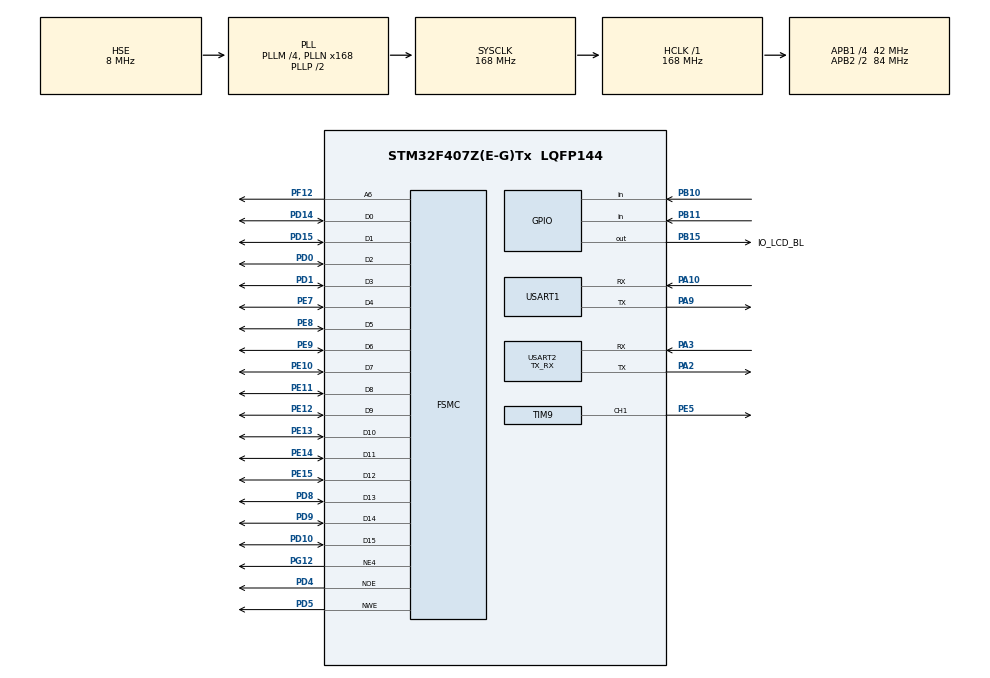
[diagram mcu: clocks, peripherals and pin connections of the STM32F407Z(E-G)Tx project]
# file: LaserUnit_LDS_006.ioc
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FSMC.AddressSetupTime1=15
FSMC.BusTurnAroundDuration1=0
FSMC.DataSetupTime1=70
FSMC.ExtendedBusTurnAroundDuration1=0
FSMC.ExtendedDataSetupTime1=15
FSMC.ExtendedMode1=FSMC_EXTENDED_MODE_ENABLE
Mcu.Family=STM32F4
Mcu.Name=STM32F407Z(E-G)Tx
Mcu.Package=LQFP144
NVIC.PriorityGroup=NVIC_PRIORITYGROUP_4
NVIC.USART2_IRQn=true\:0\:0\:false\:false\:true\:true\:true
PA10.Mode=Asynchronous
PA10.Signal=USART1_RX
PA13.Mode=Serial_Wire
PA13.Signal=SYS_JTMS-SWDIO
PA14.Mode=Serial_Wire
PA14.Signal=SYS_JTCK-SWCLK
PA2.Mode=Asynchronous
PA2.Signal=USART2_TX
PA3.Mode=Asynchronous
PA3.Signal=USART2_RX
PA9.Mode=Asynchronous
PA9.Signal=USART1_TX
PB10.GPIO_PuPd=GPIO_PULLUP
PB10.Signal=GPIO_Input
PB11.GPIO_PuPd=GPIO_PULLUP
PB11.Signal=GPIO_Input
PB15.GPIO_Label=IO_LCD_BL
PB15.PinState=GPIO_PIN_SET
PB15.Signal=GPIO_Output
PC14-OSC32_IN.Mode=LSE-External-Oscillator
PC14-OSC32_IN.Signal=RCC_OSC32_IN
PC15-OSC32_OUT.Mode=LSE-External-Oscillator
PC15-OSC32_OUT.Signal=RCC_OSC32_OUT
PD0.Signal=FSMC_D2_DA2
PD1.Signal=FSMC_D3_DA3
PD10.Signal=FSMC_D15_DA15
PD14.Signal=FSMC_D0_DA0
PD15.Signal=FSMC_D1_DA1
PD4.Signal=FSMC_NOE
PD5.Signal=FSMC_NWE
PD8.Signal=FSMC_D13_DA13
PD9.Signal=FSMC_D14_DA14
PE10.Signal=FSMC_D7_DA7
PE11.Signal=FSMC_D8_DA8
PE12.Signal=FSMC_D9_DA9
PE13.Signal=FSMC_D10_DA10
PE14.Signal=FSMC_D11_DA11
PE15.Signal=FSMC_D12_DA12
PE5.Signal=S_TIM9_CH1
PE7.Signal=FSMC_D4_DA4
PE8.Signal=FSMC_D5_DA5
PE9.Signal=FSMC_D6_DA6
PF12.Signal=FSMC_A6
PG12.Mode=NorPsramChipSelect4_1
PG12.Signal=FSMC_NE4
PH0-OSC_IN.Mode=HSE-External-Oscillator
PH0-OSC_IN.Signal=RCC_OSC_IN
PH1-OSC_OUT.Mode=HSE-External-Oscillator
PH1-OSC_OUT.Signal=RCC_OSC_OUT
ProjectManager.HeapSize=0x200
ProjectManager.StackSize=0x400
ProjectManager.TargetToolchain=STM32CubeIDE
RCC.48MHZClocksFreq_Value=84000000
RCC.AHBFreq_Value=168000000
RCC.APB1CLKDivider=RCC_HCLK_DIV4
RCC.APB1Freq_Value=42000000
RCC.APB1TimFreq_Value=84000000
RCC.APB2CLKDivider=RCC_HCLK_DIV2
RCC.APB2Freq_Value=84000000
RCC.APB2TimFreq_Value=168000000
RCC.CortexFreq_Value=168000000
RCC.HCLKFreq_Value=168000000
RCC.HSE_VALUE=8000000
RCC.HSI_VALUE=16000000
RCC.PLLM=4
RCC.PLLN=168
RCC.PLLSourceVirtual=RCC_PLLSOURCE_HSE
RCC.SYSCLKFreq_VALUE=168000000
RCC.SYSCLKSource=RCC_SYSCLKSOURCE_PLLCLK
RCC.VCOOutputFreq_Value=336000000
SH.FSMC_A6.0=FSMC_A6,A6_1
SH.FSMC_D0_DA0.0=FSMC_D0,16b-d1
SH.FSMC_D10_DA10.0=FSMC_D10,16b-d1
SH.FSMC_D11_DA11.0=FSMC_D11,16b-d1
SH.FSMC_D12_DA12.0=FSMC_D12,16b-d1
SH.FSMC_D13_DA13.0=FSMC_D13,16b-d1
SH.FSMC_D14_DA14.0=FSMC_D14,16b-d1
SH.FSMC_D15_DA15.0=FSMC_D15,16b-d1
SH.FSMC_D1_DA1.0=FSMC_D1,16b-d1
SH.FSMC_D2_DA2.0=FSMC_D2,16b-d1
SH.FSMC_D3_DA3.0=FSMC_D3,16b-d1
SH.FSMC_D4_DA4.0=FSMC_D4,16b-d1
SH.FSMC_D5_DA5.0=FSMC_D5,16b-d1
SH.FSMC_D6_DA6.0=FSMC_D6,16b-d1
SH.FSMC_D7_DA7.0=FSMC_D7,16b-d1
SH.FSMC_D8_DA8.0=FSMC_D8,16b-d1
SH.FSMC_D9_DA9.0=FSMC_D9,16b-d1
SH.FSMC_NOE.0=FSMC_NOE,Lcd1
SH.FSMC_NWE.0=FSMC_NWE,Lcd1
SH.S_TIM9_CH1.0=TIM9_CH1,PWM Generation1 CH1
TIM9.AutoReloadPreload=TIM_AUTORELOAD_PRELOAD_ENABLE
TIM9.Channel-PWM\ Generation1\ CH1=TIM_CHANNEL_1
TIM9.Period=16799
USART1.VirtualMode=VM_ASYNC
USART2.Mode=MODE_TX_RX
USART2.VirtualMode=VM_ASYNC
VP_TIM9_VS_ClockSourceINT.Mode=Internal
board=custom

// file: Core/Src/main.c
/* USER CODE BEGIN Header */
/**
  ******************************************************************************
  * @file           : main.c
  * @brief          : Main program body
  ******************************************************************************
  * @attention
  *
  * <h2><center>&copy; Copyright (c) 2021 STMicroelectronics.
  * All rights reserved.</center></h2>
  *
  * This software component is licensed by ST under BSD 3-Clause license,
  * the "License"; You may not use this file except in compliance with the
  * License. You may obtain a copy of the License at:
  *                        opensource.org/licenses/BSD-3-Clause
  *
  ******************************************************************************
  */
/* USER CODE END Header */
#include "main.h"

/* USER CODE BEGIN Includes */
#include "user_main.h"
/* USER CODE END Includes */

TIM_HandleTypeDef htim9;

UART_HandleTypeDef huart1;
UART_HandleTypeDef huart2;

SRAM_HandleTypeDef hsram1;

void SystemClock_Config(void);
static void MX_GPIO_Init(void);
static void MX_FSMC_Init(void);
static void MX_USART1_UART_Init(void);
static void MX_USART2_UART_Init(void);
static void MX_TIM9_Init(void);

int main(void)
{

  /* MCU Configuration--------------------------------------------------------*/

  /* Reset of all peripherals, Initializes the Flash interface and the Systick. */
  HAL_Init();

  /* Configure the system clock */
  SystemClock_Config();

  /* Initialize all configured peripherals */
  MX_GPIO_Init();
  MX_FSMC_Init();
  MX_USART1_UART_Init();
  MX_USART2_UART_Init();
  MX_TIM9_Init();

  /* Infinite loop */
  /* USER CODE BEGIN WHILE */
  while (1)
  {
    userMain();
    /* USER CODE END WHILE */

  }
}

void SystemClock_Config(void)
{
  RCC_OscInitTypeDef RCC_OscInitStruct = {0};
  RCC_ClkInitTypeDef RCC_ClkInitStruct = {0};

  /** Configure the main internal regulator output voltage
  */
  __HAL_RCC_PWR_CLK_ENABLE();
  __HAL_PWR_VOLTAGESCALING_CONFIG(PWR_REGULATOR_VOLTAGE_SCALE1);
  /** Initializes the RCC Oscillators according to the specified parameters
  * in the RCC_OscInitTypeDef structure.
  */
  RCC_OscInitStruct.OscillatorType = RCC_OSCILLATORTYPE_HSE;
  RCC_OscInitStruct.HSEState = RCC_HSE_ON;
  RCC_OscInitStruct.PLL.PLLState = RCC_PLL_ON;
  RCC_OscInitStruct.PLL.PLLSource = RCC_PLLSOURCE_HSE;
  RCC_OscInitStruct.PLL.PLLM = 4;
  RCC_OscInitStruct.PLL.PLLN = 168;
  RCC_OscInitStruct.PLL.PLLP = RCC_PLLP_DIV2;
  RCC_OscInitStruct.PLL.PLLQ = 4;
  if (HAL_RCC_OscConfig(&RCC_OscInitStruct) != HAL_OK)
  {
    Error_Handler();
  }
  /** Initializes the CPU, AHB and APB buses clocks
  */
  RCC_ClkInitStruct.ClockType = RCC_CLOCKTYPE_HCLK|RCC_CLOCKTYPE_SYSCLK
                              |RCC_CLOCKTYPE_PCLK1|RCC_CLOCKTYPE_PCLK2;
  RCC_ClkInitStruct.SYSCLKSource = RCC_SYSCLKSOURCE_PLLCLK;
  RCC_ClkInitStruct.AHBCLKDivider = RCC_SYSCLK_DIV1;
  RCC_ClkInitStruct.APB1CLKDivider = RCC_HCLK_DIV4;
  RCC_ClkInitStruct.APB2CLKDivider = RCC_HCLK_DIV2;

  if (HAL_RCC_ClockConfig(&RCC_ClkInitStruct, FLASH_LATENCY_5) != HAL_OK)
  {
    Error_Handler();
  }
}

static void MX_TIM9_Init(void)
{

  TIM_ClockConfigTypeDef sClockSourceConfig = {0};
  TIM_OC_InitTypeDef sConfigOC = {0};

  htim9.Instance = TIM9;
  htim9.Init.Prescaler = 0;
  htim9.Init.CounterMode = TIM_COUNTERMODE_UP;
  htim9.Init.Period = 16799;
  htim9.Init.ClockDivision = TIM_CLOCKDIVISION_DIV1;
  htim9.Init.AutoReloadPreload = TIM_AUTORELOAD_PRELOAD_ENABLE;
  if (HAL_TIM_Base_Init(&htim9) != HAL_OK)
  {
    Error_Handler();
  }
  sClockSourceConfig.ClockSource = TIM_CLOCKSOURCE_INTERNAL;
  if (HAL_TIM_ConfigClockSource(&htim9, &sClockSourceConfig) != HAL_OK)
  {
    Error_Handler();
  }
  if (HAL_TIM_PWM_Init(&htim9) != HAL_OK)
  {
    Error_Handler();
  }
  sConfigOC.OCMode = TIM_OCMODE_PWM1;
  sConfigOC.Pulse = 0;
  sConfigOC.OCPolarity = TIM_OCPOLARITY_HIGH;
  sConfigOC.OCFastMode = TIM_OCFAST_DISABLE;
  if (HAL_TIM_PWM_ConfigChannel(&htim9, &sConfigOC, TIM_CHANNEL_1) != HAL_OK)
  {
    Error_Handler();
  }
  HAL_TIM_MspPostInit(&htim9);

}

static void MX_USART1_UART_Init(void)
{

  huart1.Instance = USART1;
  huart1.Init.BaudRate = 115200;
  huart1.Init.WordLength = UART_WORDLENGTH_8B;
  huart1.Init.StopBits = UART_STOPBITS_1;
  huart1.Init.Parity = UART_PARITY_NONE;
  huart1.Init.Mode = UART_MODE_TX_RX;
  huart1.Init.HwFlowCtl = UART_HWCONTROL_NONE;
  huart1.Init.OverSampling = UART_OVERSAMPLING_16;
  if (HAL_UART_Init(&huart1) != HAL_OK)
  {
    Error_Handler();
  }

}

static void MX_USART2_UART_Init(void)
{

  huart2.Instance = USART2;
  huart2.Init.BaudRate = 115200;
  huart2.Init.WordLength = UART_WORDLENGTH_8B;
  huart2.Init.StopBits = UART_STOPBITS_1;
  huart2.Init.Parity = UART_PARITY_NONE;
  huart2.Init.Mode = UART_MODE_TX_RX;
  huart2.Init.HwFlowCtl = UART_HWCONTROL_NONE;
  huart2.Init.OverSampling = UART_OVERSAMPLING_16;
  if (HAL_UART_Init(&huart2) != HAL_OK)
  {
    Error_Handler();
  }

}

static void MX_GPIO_Init(void)
{
  GPIO_InitTypeDef GPIO_InitStruct = {0};

  /* GPIO Ports Clock Enable */
  __HAL_RCC_GPIOE_CLK_ENABLE();
  __HAL_RCC_GPIOC_CLK_ENABLE();
  __HAL_RCC_GPIOH_CLK_ENABLE();
  __HAL_RCC_GPIOA_CLK_ENABLE();
  __HAL_RCC_GPIOF_CLK_ENABLE();
  __HAL_RCC_GPIOB_CLK_ENABLE();
  __HAL_RCC_GPIOD_CLK_ENABLE();
  __HAL_RCC_GPIOG_CLK_ENABLE();

  /*Configure GPIO pin Output Level */
  HAL_GPIO_WritePin(IO_LCD_BL_GPIO_Port, IO_LCD_BL_Pin, GPIO_PIN_SET);

  /*Configure GPIO pins : PB10 PB11 */
  GPIO_InitStruct.Pin = GPIO_PIN_10|GPIO_PIN_11;
  GPIO_InitStruct.Mode = GPIO_MODE_INPUT;
  GPIO_InitStruct.Pull = GPIO_PULLUP;
  HAL_GPIO_Init(GPIOB, &GPIO_InitStruct);

  /*Configure GPIO pin : IO_LCD_BL_Pin */
  GPIO_InitStruct.Pin = IO_LCD_BL_Pin;
  GPIO_InitStruct.Mode = GPIO_MODE_OUTPUT_PP;
  GPIO_InitStruct.Pull = GPIO_NOPULL;
  GPIO_InitStruct.Speed = GPIO_SPEED_FREQ_LOW;
  HAL_GPIO_Init(IO_LCD_BL_GPIO_Port, &GPIO_InitStruct);

}

/* FSMC initialization function */
static void MX_FSMC_Init(void)
{

  FSMC_NORSRAM_TimingTypeDef Timing = {0};
  FSMC_NORSRAM_TimingTypeDef ExtTiming = {0};

  /** Perform the SRAM1 memory initialization sequence
  */
  hsram1.Instance = FSMC_NORSRAM_DEVICE;
  hsram1.Extended = FSMC_NORSRAM_EXTENDED_DEVICE;
  /* hsram1.Init */
  hsram1.Init.NSBank = FSMC_NORSRAM_BANK4;
  hsram1.Init.DataAddressMux = FSMC_DATA_ADDRESS_MUX_DISABLE;
  hsram1.Init.MemoryType = FSMC_MEMORY_TYPE_SRAM;
  hsram1.Init.MemoryDataWidth = FSMC_NORSRAM_MEM_BUS_WIDTH_16;
  hsram1.Init.BurstAccessMode = FSMC_BURST_ACCESS_MODE_DISABLE;
  hsram1.Init.WaitSignalPolarity = FSMC_WAIT_SIGNAL_POLARITY_LOW;
  hsram1.Init.WrapMode = FSMC_WRAP_MODE_DISABLE;
  hsram1.Init.WaitSignalActive = FSMC_WAIT_TIMING_BEFORE_WS;
  hsram1.Init.WriteOperation = FSMC_WRITE_OPERATION_ENABLE;
  hsram1.Init.WaitSignal = FSMC_WAIT_SIGNAL_DISABLE;
  hsram1.Init.ExtendedMode = FSMC_EXTENDED_MODE_ENABLE;
  hsram1.Init.AsynchronousWait = FSMC_ASYNCHRONOUS_WAIT_DISABLE;
  hsram1.Init.WriteBurst = FSMC_WRITE_BURST_DISABLE;
  hsram1.Init.PageSize = FSMC_PAGE_SIZE_NONE;
  /* Timing */
  Timing.AddressSetupTime = 15;
  Timing.AddressHoldTime = 15;
  Timing.DataSetupTime = 70;
  Timing.BusTurnAroundDuration = 0;
  Timing.CLKDivision = 16;
  Timing.DataLatency = 17;
  Timing.AccessMode = FSMC_ACCESS_MODE_A;
  /* ExtTiming */
  ExtTiming.AddressSetupTime = 15;
  ExtTiming.AddressHoldTime = 15;
  ExtTiming.DataSetupTime = 15;
  ExtTiming.BusTurnAroundDuration = 0;
  ExtTiming.CLKDivision = 16;
  ExtTiming.DataLatency = 17;
  ExtTiming.AccessMode = FSMC_ACCESS_MODE_A;

  if (HAL_SRAM_Init(&hsram1, &Timing, &ExtTiming) != HAL_OK)
  {
    Error_Handler( );
  }

}

void Error_Handler(void)
{
  __disable_irq();
  while (1)
  {
  }
}

/************************ (C) COPYRIGHT STMicroelectronics *****END OF FILE****/
